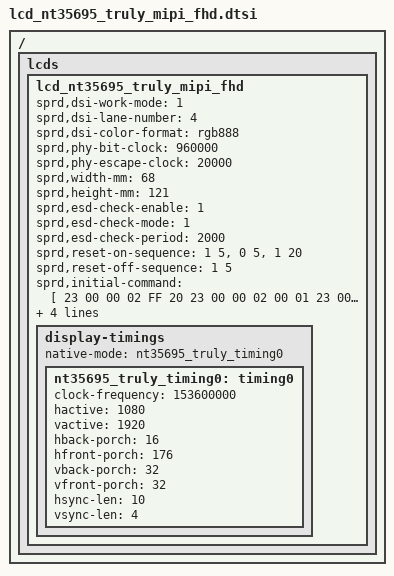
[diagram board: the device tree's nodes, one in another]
// SPDX-License-Identifier: GPL-2.0-only
/*
 * Unisoc NT35696 Truly LCD config DTS file
 *
 * Copyright (C) 2021, Unisoc Inc.
 */
/ {
	fragment {
		target-path = "/";
		__overlay__ {
			lcds {
				lcd_nt35695_truly_mipi_fhd: lcd_nt35695_truly_mipi_fhd {

					sprd,dsi-work-mode = <1>; /* video burst mode*/
					sprd,dsi-lane-number = <4>;
					sprd,dsi-color-format = "rgb888";

					sprd,phy-bit-clock = <960000>;	/* kbps */
					sprd,phy-escape-clock = <20000>;/* kHz */

					sprd,width-mm = <68>;
					sprd,height-mm = <121>;

					sprd,esd-check-enable = <1>;
					sprd,esd-check-mode = <1>;
					sprd,esd-check-period = <2000>;
					/* sprd,esd-check-regs = <0xA>; */
					/* sprd,esd-return-code = <0x9c>; */

					sprd,reset-on-sequence = <1 5>, <0 5>, <1 20>;
					sprd,reset-off-sequence = <1 5>;

					sprd,initial-command = [
						//CMD2_P0
						23 00 00 02 FF 20

						23 00 00 02 00 01
						23 00 00 02 01 55
						23 00 00 02 02 45
						23 00 00 02 03 55
						23 00 00 02 05 50
						23 00 00 02 06 4A
						23 00 00 02 07 24
						23 00 00 02 08 0C
						23 00 00 02 0B 87
						23 00 00 02 0C 87
						23 00 00 02 0E B0
						23 00 00 02 0F B3
						23 00 00 02 11 25//10 VCOM 171201
						23 00 00 02 12 10
						23 00 00 02 13 03
						23 00 00 02 14 4A
						23 00 00 02 15 12
						23 00 00 02 16 12
						23 00 00 02 30 01

						23 00 00 02 58 82
						23 00 00 02 59 00
						23 00 00 02 5A 02
						23 00 00 02 5B 00
						23 00 00 02 5C 82
						23 00 00 02 5D 82
						23 00 00 02 5E 02
						23 00 00 02 5F 02

						23 00 00 02 72 31
						23 00 00 02 FB 01


						//page selection cmd start
						//23 00 00 02 FF 20
						//page selection cmd end
						//R(+) MCR cmd
						23 00 00 02 75 00
						23 00 00 02 76 00
						23 00 00 02 77 00
						23 00 00 02 78 06
						23 00 00 02 79 00
						23 00 00 02 7A 1A
						23 00 00 02 7B 00
						23 00 00 02 7C 37
						23 00 00 02 7D 00
						23 00 00 02 7E 5A
						23 00 00 02 7F 00
						23 00 00 02 80 75
						23 00 00 02 81 00
						23 00 00 02 82 8D
						23 00 00 02 83 00
						23 00 00 02 84 A0
						23 00 00 02 85 00
						23 00 00 02 86 B1
						23 00 00 02 87 00
						23 00 00 02 88 E4
						23 00 00 02 89 01
						23 00 00 02 8A 07
						23 00 00 02 8B 01
						23 00 00 02 8C 36
						23 00 00 02 8D 01
						23 00 00 02 8E 5D
						23 00 00 02 8F 01
						23 00 00 02 90 A9
						23 00 00 02 91 01
						23 00 00 02 92 E1
						23 00 00 02 93 01
						23 00 00 02 94 E3
						23 00 00 02 95 02
						23 00 00 02 96 11
						23 00 00 02 97 02
						23 00 00 02 98 54
						23 00 00 02 99 02
						23 00 00 02 9A 7F
						23 00 00 02 9B 02
						23 00 00 02 9C BD
						23 00 00 02 9D 02
						23 00 00 02 9E E5
						23 00 00 02 9F 03
						23 00 00 02 A0 1B
						23 00 00 02 A2 03
						23 00 00 02 A3 25
						23 00 00 02 A4 03
						23 00 00 02 A5 28
						23 00 00 02 A6 03
						23 00 00 02 A7 3A
						23 00 00 02 A9 03
						23 00 00 02 AA 5D
						23 00 00 02 AB 03
						23 00 00 02 AC A4
						23 00 00 02 AD 03
						23 00 00 02 AE C1
						23 00 00 02 AF 03
						23 00 00 02 B0 D3
						23 00 00 02 B1 03
						23 00 00 02 B2 D8
						//R(-) MCR cmd
						23 00 00 02 B3 00
						23 00 00 02 B4 00
						23 00 00 02 B5 00
						23 00 00 02 B6 06
						23 00 00 02 B7 00
						23 00 00 02 B8 1A
						23 00 00 02 B9 00
						23 00 00 02 BA 37
						23 00 00 02 BB 00
						23 00 00 02 BC 5A
						23 00 00 02 BD 00
						23 00 00 02 BE 75
						23 00 00 02 BF 00
						23 00 00 02 C0 8D
						23 00 00 02 C1 00
						23 00 00 02 C2 A0
						23 00 00 02 C3 00
						23 00 00 02 C4 B1
						23 00 00 02 C5 00
						23 00 00 02 C6 E4
						23 00 00 02 C7 01
						23 00 00 02 C8 07
						23 00 00 02 C9 01
						23 00 00 02 CA 36
						23 00 00 02 CB 01
						23 00 00 02 CC 5D
						23 00 00 02 CD 01
						23 00 00 02 CE A9
						23 00 00 02 CF 01
						23 00 00 02 D0 E1
						23 00 00 02 D1 01
						23 00 00 02 D2 E3
						23 00 00 02 D3 02
						23 00 00 02 D4 11
						23 00 00 02 D5 02
						23 00 00 02 D6 54
						23 00 00 02 D7 02
						23 00 00 02 D8 7F
						23 00 00 02 D9 02
						23 00 00 02 DA BD
						23 00 00 02 DB 02
						23 00 00 02 DC E5
						23 00 00 02 DD 03
						23 00 00 02 DE 1B
						23 00 00 02 DF 03
						23 00 00 02 E0 25
						23 00 00 02 E1 03
						23 00 00 02 E2 28
						23 00 00 02 E3 03
						23 00 00 02 E4 3A
						23 00 00 02 E5 03
						23 00 00 02 E6 5D
						23 00 00 02 E7 03
						23 00 00 02 E8 A4
						23 00 00 02 E9 03
						23 00 00 02 EA C1
						23 00 00 02 EB 03
						23 00 00 02 EC D3
						23 00 00 02 ED 03
						23 00 00 02 EE D8
						//G(+) MCR cmd
						23 00 00 02 EF 00
						23 00 00 02 F0 BA
						23 00 00 02 F1 00
						23 00 00 02 F2 C1
						23 00 00 02 F3 00
						23 00 00 02 F4 D1
						23 00 00 02 F5 00
						23 00 00 02 F6 DE
						23 00 00 02 F7 00
						23 00 00 02 F8 E7
						23 00 00 02 F9 00
						23 00 00 02 FA F0
						//page selection cmd start
						23 00 00 02 FF 21
						//page selection cmd end
						23 00 00 02 00 00
						23 00 00 02 01 FA
						23 00 00 02 02 01
						23 00 00 02 03 03
						23 00 00 02 04 01
						23 00 00 02 05 0E
						23 00 00 02 06 01
						23 00 00 02 07 33
						23 00 00 02 08 01
						23 00 00 02 09 4C
						23 00 00 02 0A 01
						23 00 00 02 0B 6D
						23 00 00 02 0C 01
						23 00 00 02 0D 8A
						23 00 00 02 0E 01
						23 00 00 02 0F C0
						23 00 00 02 10 01
						23 00 00 02 11 EF
						23 00 00 02 12 01
						23 00 00 02 13 F1
						23 00 00 02 14 02
						23 00 00 02 15 20
						23 00 00 02 16 02
						23 00 00 02 17 63
						23 00 00 02 18 02
						23 00 00 02 19 91
						23 00 00 02 1A 02
						23 00 00 02 1B CF
						23 00 00 02 1C 02
						23 00 00 02 1D F9
						23 00 00 02 1E 03
						23 00 00 02 1F 31
						23 00 00 02 20 03
						23 00 00 02 21 3D
						23 00 00 02 22 03
						23 00 00 02 23 40
						23 00 00 02 24 03
						23 00 00 02 25 51
						23 00 00 02 26 03
						23 00 00 02 27 71
						23 00 00 02 28 03
						23 00 00 02 29 85
						23 00 00 02 2A 03
						23 00 00 02 2B AB
						23 00 00 02 2D 03
						23 00 00 02 2F D6
						23 00 00 02 30 03
						23 00 00 02 31 D8
						//G(-) MCR cmd
						23 00 00 02 32 00
						23 00 00 02 33 BA
						23 00 00 02 34 00
						23 00 00 02 35 C1
						23 00 00 02 36 00
						23 00 00 02 37 D1
						23 00 00 02 38 00
						23 00 00 02 39 DE
						23 00 00 02 3A 00
						23 00 00 02 3B E7
						23 00 00 02 3D 00
						23 00 00 02 3F F0
						23 00 00 02 40 00
						23 00 00 02 41 FA
						23 00 00 02 42 01
						23 00 00 02 43 03
						23 00 00 02 44 01
						23 00 00 02 45 0E
						23 00 00 02 46 01
						23 00 00 02 47 33
						23 00 00 02 48 01
						23 00 00 02 49 4C
						23 00 00 02 4A 01
						23 00 00 02 4B 6D
						23 00 00 02 4C 01
						23 00 00 02 4D 8A
						23 00 00 02 4E 01
						23 00 00 02 4F C0
						23 00 00 02 50 01
						23 00 00 02 51 EF
						23 00 00 02 52 01
						23 00 00 02 53 F1
						23 00 00 02 54 02
						23 00 00 02 55 20
						23 00 00 02 56 02
						23 00 00 02 58 63
						23 00 00 02 59 02
						23 00 00 02 5A 91
						23 00 00 02 5B 02
						23 00 00 02 5C CF
						23 00 00 02 5D 02
						23 00 00 02 5E F9
						23 00 00 02 5F 03
						23 00 00 02 60 31
						23 00 00 02 61 03
						23 00 00 02 62 3D
						23 00 00 02 63 03
						23 00 00 02 64 40
						23 00 00 02 65 03
						23 00 00 02 66 51
						23 00 00 02 67 03
						23 00 00 02 68 71
						23 00 00 02 69 03
						23 00 00 02 6A 85
						23 00 00 02 6B 03
						23 00 00 02 6C AB
						23 00 00 02 6D 03
						23 00 00 02 6E D6
						23 00 00 02 6F 03
						23 00 00 02 70 D8
						//B(+) MCR cmd
						23 00 00 02 71 00
						23 00 00 02 72 A7
						23 00 00 02 73 00
						23 00 00 02 74 AE
						23 00 00 02 75 00
						23 00 00 02 76 BD
						23 00 00 02 77 00
						23 00 00 02 78 CA
						23 00 00 02 79 00
						23 00 00 02 7A D4
						23 00 00 02 7B 00
						23 00 00 02 7C DD
						23 00 00 02 7D 00
						23 00 00 02 7E E6
						23 00 00 02 7F 00
						23 00 00 02 80 EF
						23 00 00 02 81 00
						23 00 00 02 82 F9
						23 00 00 02 83 01
						23 00 00 02 84 1D
						23 00 00 02 85 01
						23 00 00 02 86 36
						23 00 00 02 87 01
						23 00 00 02 88 5B
						23 00 00 02 89 01
						23 00 00 02 8A 79
						23 00 00 02 8B 01
						23 00 00 02 8C BA
						23 00 00 02 8D 01
						23 00 00 02 8E EA
						23 00 00 02 8F 01
						23 00 00 02 90 ED
						23 00 00 02 91 02
						23 00 00 02 92 1B
						23 00 00 02 93 02
						23 00 00 02 94 5F
						23 00 00 02 95 02
						23 00 00 02 96 8A
						23 00 00 02 97 02
						23 00 00 02 98 CC
						23 00 00 02 99 02
						23 00 00 02 9A FB
						23 00 00 02 9B 03
						23 00 00 02 9C 61
						23 00 00 02 9D 03
						23 00 00 02 9E AF
						23 00 00 02 9F 03
						23 00 00 02 A0 C6
						23 00 00 02 A2 03
						23 00 00 02 A3 CC
						23 00 00 02 A4 03
						23 00 00 02 A5 CE
						23 00 00 02 A6 03
						23 00 00 02 A7 D2
						23 00 00 02 A9 03
						23 00 00 02 AA D4
						23 00 00 02 AB 03
						23 00 00 02 AC D7
						23 00 00 02 AD 03
						23 00 00 02 AE D8
						//B(-) MCR cmd
						23 00 00 02 AF 00
						23 00 00 02 B0 A7
						23 00 00 02 B1 00
						23 00 00 02 B2 AE
						23 00 00 02 B3 00
						23 00 00 02 B4 BD
						23 00 00 02 B5 00
						23 00 00 02 B6 CA
						23 00 00 02 B7 00
						23 00 00 02 B8 D4
						23 00 00 02 B9 00
						23 00 00 02 BA DD
						23 00 00 02 BB 00
						23 00 00 02 BC E6
						23 00 00 02 BD 00
						23 00 00 02 BE EF
						23 00 00 02 BF 00
						23 00 00 02 C0 F9
						23 00 00 02 C1 01
						23 00 00 02 C2 1D
						23 00 00 02 C3 01
						23 00 00 02 C4 36
						23 00 00 02 C5 01
						23 00 00 02 C6 5B
						23 00 00 02 C7 01
						23 00 00 02 C8 79
						23 00 00 02 C9 01
						23 00 00 02 CA BA
						23 00 00 02 CB 01
						23 00 00 02 CC EA
						23 00 00 02 CD 01
						23 00 00 02 CE ED
						23 00 00 02 CF 02
						23 00 00 02 D0 1B
						23 00 00 02 D1 02
						23 00 00 02 D2 5F
						23 00 00 02 D3 02
						23 00 00 02 D4 8A
						23 00 00 02 D5 02
						23 00 00 02 D6 CC
						23 00 00 02 D7 02
						23 00 00 02 D8 FB
						23 00 00 02 D9 03
						23 00 00 02 DA 61
						23 00 00 02 DB 03
						23 00 00 02 DC AF
						23 00 00 02 DD 03
						23 00 00 02 DE C6
						23 00 00 02 DF 03
						23 00 00 02 E0 CC
						23 00 00 02 E1 03
						23 00 00 02 E2 CE
						23 00 00 02 E3 03
						23 00 00 02 E4 D2
						23 00 00 02 E5 03
						23 00 00 02 E6 D4
						23 00 00 02 E7 03
						23 00 00 02 E8 D7
						23 00 00 02 E9 03
						23 00 00 02 EA D8

						//CMD2_P4
						23 00 00 02 FF 24
						23 00 00 02 00 01
						23 00 00 02 01 0B
						23 00 00 02 02 0C
						23 00 00 02 03 09
						23 00 00 02 04 0A
						23 00 00 02 05 1C
						23 00 00 02 06 10
						23 00 00 02 07 00
						23 00 00 02 08 1C
						23 00 00 02 09 00
						23 00 00 02 0A 00
						23 00 00 02 0B 00
						23 00 00 02 0C 00
						23 00 00 02 0D 13
						23 00 00 02 0E 15
						23 00 00 02 0F 17
						23 00 00 02 10 01
						23 00 00 02 11 0B
						23 00 00 02 12 0C
						23 00 00 02 13 09
						23 00 00 02 14 0A
						23 00 00 02 15 1C
						23 00 00 02 16 10
						23 00 00 02 17 10
						23 00 00 02 18 1C
						23 00 00 02 19 00
						23 00 00 02 1A 00
						23 00 00 02 1B 00
						23 00 00 02 1C 00
						23 00 00 02 1D 13
						23 00 00 02 1E 15
						23 00 00 02 1F 17

						23 00 00 02 20 00
						23 00 00 02 21 03
						23 00 00 02 22 01
						23 00 00 02 23 4A
						23 00 00 02 24 4A
						//23 00 00 02 23 40
						//23 00 00 02 24 40
						23 00 00 02 25 6D
						23 00 00 02 26 40
						23 00 00 02 27 40

						23 00 00 02 BD 20
						23 00 00 02 B6 22
						23 00 00 02 B7 24
						23 00 00 02 B8 07
						23 00 00 02 B9 07
						23 00 00 02 C1 6D
						23 00 00 02 BE 07
						23 00 00 02 BF 07

						23 00 00 02 29 D8
						23 00 00 02 2A 2A

						23 00 00 02 4B 04
						23 00 00 02 4C 12
						23 00 00 02 4D 00
						23 00 00 02 4E 22
						23 00 00 02 4F 22
						23 00 00 02 50 00
						23 00 00 02 51 61
						23 00 00 02 52 01
						23 00 00 02 53 08
						23 00 00 02 56 08
						23 00 00 02 54 8A
						23 00 00 02 58 8A
						//23 00 00 02 53 06
						//23 00 00 02 56 06
						//23 00 00 02 54 8E
						//23 00 00 02 58 8E
						23 00 00 02 55 6D

						23 00 00 02 5B 43
						23 00 00 02 5C 00
						23 00 00 02 5F 73
						23 00 00 02 60 73
						23 00 00 02 63 22
						23 00 00 02 64 00
						23 00 00 02 67 08
						23 00 00 02 68 04

						23 00 00 02 7A 80
						23 00 00 02 7B 91
						23 00 00 02 7C D8
						23 00 00 02 7D 60
						23 00 00 02 75 20
						23 00 00 02 7F 20
						23 00 00 02 74 10
						23 00 00 02 7E 10

						23 00 00 02 93 06
						23 00 00 02 94 06

						23 00 00 02 B3 00
						23 00 00 02 B4 00
						23 00 00 02 B5 00

						23 00 00 02 78 00
						23 00 00 02 79 00
						23 00 00 02 80 00
						23 00 00 02 83 00
						23 00 00 02 84 04

						23 00 00 02 8A 33
						23 00 00 02 9B 0F
						23 00 00 02 8B F0

						//BK_EN
						23 00 00 02 E3 00

						23 00 00 02 FB 01

						//23 00 00 02 C4 99
						//23 00 00 02 C5 99
						//23 00 00 02 C6 99

						23 00 00 02 EC 00


						//CMD1
						23 00 00 02 FF 10
						29 00 00 04 3B 03 24 20

						//TE ModeC at 1280th line
						23 00 00 02 35 00
						//29 00 00 03 44 05 00
						23 00 00 02 BB 03

						//CABC ON
						29 00 00 03 51 FF 00
						23 00 00 02 53 2C
						23 00 00 02 55 00

						//pause
						13 50 00 01 11
						13 14 00 01 29
						];

					sprd,sleep-in-command = [
						13 01 00 01 00
						13 0A 00 01 28
						13 78 00 01 10
						23 0a 00 02 4F 01
						];

					sprd,sleep-out-command = [
						13 50 00 01 11
						13 14 00 01 29
						];

					display-timings {
						native-mode = <&nt35695_truly_timing0>;

						nt35695_truly_timing0: timing0 {
							clock-frequency = <153600000>;
							hactive = <1080>;
							vactive = <1920>;
							hback-porch = <16>;
							hfront-porch = <176>;
							vback-porch = <32>;
							vfront-porch = <32>;
							hsync-len = <10>;
							vsync-len = <4>;
						};
					};
				};
			};
		};
	};
};
